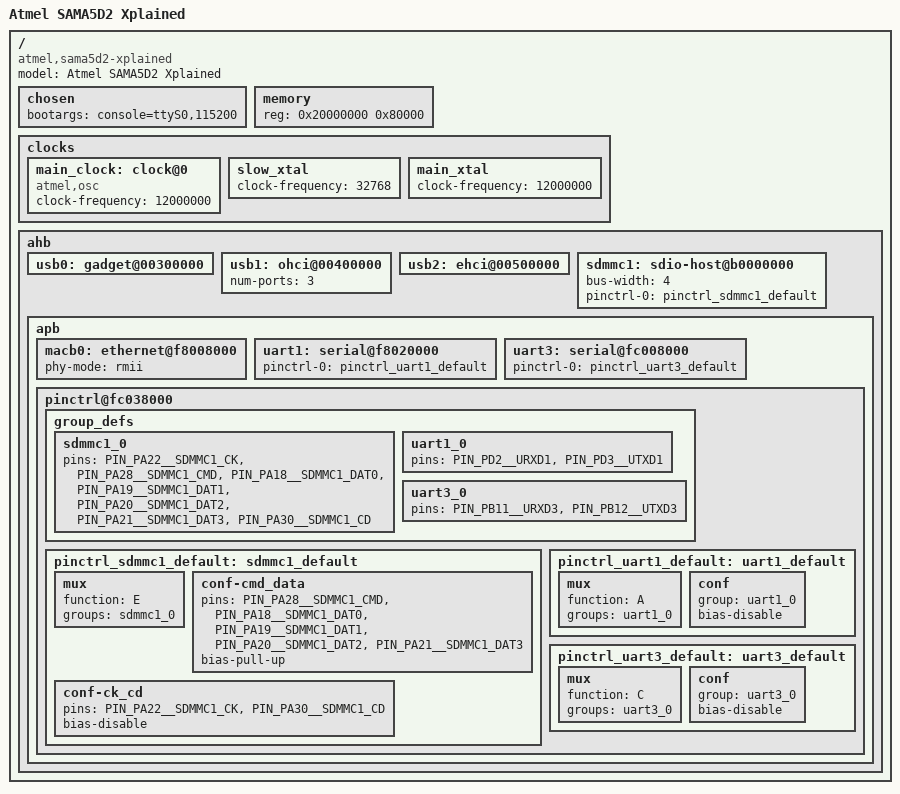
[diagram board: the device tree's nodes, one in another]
/*
 * at91-sama5d2_xplained.dts - Device Tree file for SAMA5D2 Xplained board
 *
 *  Copyright (C) 2015 Atmel,
 *                2015 Nicolas Ferre <nicolas.ferre@atmel.com>
 *
 * This file is dual-licensed: you can use it either under the terms
 * of the GPL or the X11 license, at your option. Note that this dual
 * licensing only applies to this file, and not this project as a
 * whole.
 *
 *  a) This file is free software; you can redistribute it and/or
 *     modify it under the terms of the GNU General Public License as
 *     published by the Free Software Foundation; either version 2 of the
 *     License, or (at your option) any later version.
 *
 *     This file is distributed in the hope that it will be useful,
 *     but WITHOUT ANY WARRANTY; without even the implied warranty of
 *     MERCHANTABILITY or FITNESS FOR A PARTICULAR PURPOSE.  See the
 *     GNU General Public License for more details.
 *
 * Or, alternatively,
 *
 *  b) Permission is hereby granted, free of charge, to any person
 *     obtaining a copy of this software and associated documentation
 *     files (the "Software"), to deal in the Software without
 *     restriction, including without limitation the rights to use,
 *     copy, modify, merge, publish, distribute, sublicense, and/or
 *     sell copies of the Software, and to permit persons to whom the
 *     Software is furnished to do so, subject to the following
 *     conditions:
 *
 *     The above copyright notice and this permission notice shall be
 *     included in all copies or substantial portions of the Software.
 *
 *     THE SOFTWARE IS PROVIDED "AS IS", WITHOUT WARRANTY OF ANY KIND,
 *     EXPRESS OR IMPLIED, INCLUDING BUT NOT LIMITED TO THE WARRANTIES
 *     OF MERCHANTABILITY, FITNESS FOR A PARTICULAR PURPOSE AND
 *     NONINFRINGEMENT. IN NO EVENT SHALL THE AUTHORS OR COPYRIGHT
 *     HOLDERS BE LIABLE FOR ANY CLAIM, DAMAGES OR OTHER LIABILITY,
 *     WHETHER IN AN ACTION OF CONTRACT, TORT OR OTHERWISE, ARISING
 *     FROM, OUT OF OR IN CONNECTION WITH THE SOFTWARE OR THE USE OR
 *     OTHER DEALINGS IN THE SOFTWARE.
 */
/dts-v1/;
#include "sama5d2.dtsi"
#include "sama5d2-pinfunc.h"

/ {
	model = "Atmel SAMA5D2 Xplained";
	compatible = "atmel,sama5d2-xplained", "atmel,sama5d2", "atmel,sama5";

	chosen {
		bootargs = "console=ttyS0,115200";
	};

	memory {
		reg = <0x20000000 0x80000>;
	};

	clocks {
		#address-cells = <1>;
		#size-cells = <1>;
		ranges;

		main_clock: clock@0 {
			compatible = "atmel,osc", "fixed-clock";
			clock-frequency = <12000000>;
		};

		slow_xtal {
			clock-frequency = <32768>;
		};

		main_xtal {
			clock-frequency = <12000000>;
		};
	};

	ahb {
		usb0: gadget@00300000 {
			/* TODO: add atmel,vbus-gpio property */
			/*pinctrl-names = "default";
			pinctrl-0 = <&pinctrl_usba_vbus>;*/
			status = "okay";
		};

		usb1: ohci@00400000 {
			num-ports = <3>;
			/* TODO: add atmel,vbus-gpio property */
			/*pinctrl-names = "default";
			pinctrl-0 = <&pinctrl_usb_default>;*/
			status = "okay";
		};

		usb2: ehci@00500000 {
			status = "okay";
		};

		sdmmc1: sdio-host@b0000000 {
			bus-width = <4>;
			pinctrl-names = "default";
			pinctrl-0 = <&pinctrl_sdmmc1_default>;
			status = "okay";
		};

		apb {
			macb0: ethernet@f8008000 {
				phy-mode = "rmii";
				status = "okay";
			};

			uart1: serial@f8020000 {
				pinctrl-names = "default";
				pinctrl-0 = <&pinctrl_uart1_default>;
				status = "okay";
			};

			uart3: serial@fc008000 {
				pinctrl-names = "default";
				pinctrl-0 = <&pinctrl_uart3_default>;
				status = "okay";
			};

			pinctrl@fc038000 {
				group_defs {
					sdmmc1_0 {
						pins = <PIN_PA22__SDMMC1_CK>,
						       <PIN_PA28__SDMMC1_CMD>,
						       <PIN_PA18__SDMMC1_DAT0>,
						       <PIN_PA19__SDMMC1_DAT1>,
						       <PIN_PA20__SDMMC1_DAT2>,
						       <PIN_PA21__SDMMC1_DAT3>,
						       <PIN_PA30__SDMMC1_CD>;
					};

					uart1_0 {
						pins = <PIN_PD2__URXD1>,
						       <PIN_PD3__UTXD1>;
					};

					uart3_0 {
						pins = <PIN_PB11__URXD3>,
						       <PIN_PB12__UTXD3>;
					};
				};

				pinctrl_sdmmc1_default: sdmmc1_default {
					mux {
						function = "E";
						groups = "sdmmc1_0";
					};

					conf-cmd_data {
						pins = <PIN_PA28__SDMMC1_CMD>,
						       <PIN_PA18__SDMMC1_DAT0>,
						       <PIN_PA19__SDMMC1_DAT1>,
						       <PIN_PA20__SDMMC1_DAT2>,
						       <PIN_PA21__SDMMC1_DAT3>;
						bias-pull-up;
					};

					conf-ck_cd {
						pins = <PIN_PA22__SDMMC1_CK>,
						       <PIN_PA30__SDMMC1_CD>;
						bias-disable;
					};
				};

				pinctrl_uart1_default: uart1_default {
					mux {
						function = "A";
						groups = "uart1_0";
					};

					conf {
						group = "uart1_0";
						bias-disable;
					};
				};

				pinctrl_uart3_default: uart3_default {
					mux {
						function = "C";
						groups = "uart3_0";
					};

					conf {
						group = "uart3_0";
						bias-disable;
					};
				};
			};
		};
	};
};
